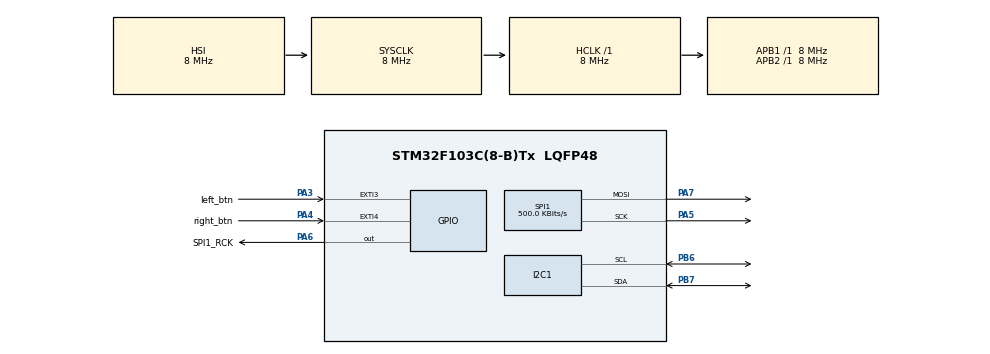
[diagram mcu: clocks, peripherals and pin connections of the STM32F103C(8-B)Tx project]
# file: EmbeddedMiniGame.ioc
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Mcu.Family=STM32F1
Mcu.Name=STM32F103C(8-B)Tx
Mcu.Package=LQFP48
NVIC.EXTI3_IRQn=true\:0\:0\:false\:false\:true\:true\:true\:true
NVIC.EXTI4_IRQn=true\:0\:0\:false\:false\:true\:true\:true\:true
NVIC.PriorityGroup=NVIC_PRIORITYGROUP_4
NVIC.TIM2_IRQn=true\:0\:0\:false\:false\:true\:true\:true\:true
NVIC.TIM3_IRQn=true\:0\:0\:false\:false\:true\:true\:true\:true
PA13.Mode=Serial_Wire
PA13.Signal=SYS_JTMS-SWDIO
PA14.Mode=Serial_Wire
PA14.Signal=SYS_JTCK-SWCLK
PA3.GPIO_Label=left_btn
PA3.GPIO_ModeDefaultEXTI=GPIO_MODE_IT_RISING_FALLING
PA3.GPIO_PuPd=GPIO_PULLUP
PA3.Signal=GPXTI3
PA4.GPIO_Label=right_btn
PA4.GPIO_ModeDefaultEXTI=GPIO_MODE_IT_RISING_FALLING
PA4.GPIO_PuPd=GPIO_PULLUP
PA4.Signal=GPXTI4
PA5.Mode=TX_Only_Simplex_Unidirect_Master
PA5.Signal=SPI1_SCK
PA6.GPIO_Label=SPI1_RCK
PA6.GPIO_PuPd=GPIO_PULLDOWN
PA6.GPIO_Speed=GPIO_SPEED_FREQ_HIGH
PA6.Signal=GPIO_Output
PA7.Mode=TX_Only_Simplex_Unidirect_Master
PA7.Signal=SPI1_MOSI
PB6.Mode=I2C
PB6.Signal=I2C1_SCL
PB7.Mode=I2C
PB7.Signal=I2C1_SDA
ProjectManager.HeapSize=0x200
ProjectManager.StackSize=0x400
ProjectManager.TargetToolchain=STM32CubeIDE
RCC.AHBFreq_Value=8000000
RCC.APB1Freq_Value=8000000
RCC.APB1TimFreq_Value=8000000
RCC.APB2Freq_Value=8000000
RCC.APB2TimFreq_Value=8000000
RCC.HCLKFreq_Value=8000000
RCC.SYSCLKFreq_VALUE=8000000
RCC.USBFreq_Value=8000000
SPI1.BaudRatePrescaler=SPI_BAUDRATEPRESCALER_16
SPI1.CLKPhase=SPI_PHASE_2EDGE
SPI1.CLKPolarity=SPI_POLARITY_HIGH
SPI1.CalculateBaudRate=500.0 KBits/s
SPI1.Direction=SPI_DIRECTION_2LINES
SPI1.Mode=SPI_MODE_MASTER
SPI1.VirtualType=VM_MASTER
TIM2.Period=3000-1
TIM2.Prescaler=8000-1
TIM3.Period=2-1
TIM3.Prescaler=8000-1
VP_TIM2_VS_ClockSourceINT.Mode=Internal
VP_TIM2_VS_ClockSourceITR.Mode=TriggerSource_ITR1
VP_TIM3_VS_ClockSourceINT.Mode=Internal
VP_TIM3_VS_ClockSourceITR.Mode=TriggerSource_ITR2
board=custom

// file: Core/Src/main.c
/* USER CODE BEGIN Header */
/**
  ******************************************************************************
  * @file           : main.c
  * @brief          : Main program body
  ******************************************************************************
  * @attention
  *
  * Copyright (c) 2026 STMicroelectronics.
  * All rights reserved.
  *
  * This software is licensed under terms that can be found in the LICENSE file
  * in the root directory of this software component.
  * If no LICENSE file comes with this software, it is provided AS-IS.
  *
  ******************************************************************************
  */
/* USER CODE END Header */
#include "main.h"

/* USER CODE BEGIN Includes */
#include "global.h"
#include "game.h"
#include "ssd1306.h"
#include "fnd.h"
/* USER CODE END Includes */

I2C_HandleTypeDef hi2c1;

SPI_HandleTypeDef hspi1;

TIM_HandleTypeDef htim2;
TIM_HandleTypeDef htim3;

void SystemClock_Config(void);
static void MX_GPIO_Init(void);
static void MX_I2C1_Init(void);
static void MX_TIM2_Init(void);
static void MX_SPI1_Init(void);
static void MX_TIM3_Init(void);

int main(void)
{

  /* MCU Configuration--------------------------------------------------------*/

  /* Reset of all peripherals, Initializes the Flash interface and the Systick. */
  HAL_Init();

  /* Configure the system clock */
  SystemClock_Config();

  /* Initialize all configured peripherals */
  MX_GPIO_Init();
  MX_I2C1_Init();
  MX_TIM2_Init();
  MX_SPI1_Init();
  MX_TIM3_Init();
  /* USER CODE BEGIN 2 */
  if (ssd1306_Init(&hi2c1) != 0) {
  	   	Error_Handler();
  }
  send_init(&hspi1);
  // ??기화�????
  GameIdle(&hi2c1,&htim2,&htim3);
  /* USER CODE END 2 */

  /* Infinite loop */
  /* USER CODE BEGIN WHILE */
  while (1)
  {
	  if(!game.is_start){
		  GameIdle(&hi2c1,&htim2,&htim3);
	  }
	  isStartBtnDown();
	  GameStart();

    /* USER CODE END WHILE */

  }
}

void SystemClock_Config(void)
{
  RCC_OscInitTypeDef RCC_OscInitStruct = {0};
  RCC_ClkInitTypeDef RCC_ClkInitStruct = {0};

  /** Initializes the RCC Oscillators according to the specified parameters
  * in the RCC_OscInitTypeDef structure.
  */
  RCC_OscInitStruct.OscillatorType = RCC_OSCILLATORTYPE_HSI;
  RCC_OscInitStruct.HSIState = RCC_HSI_ON;
  RCC_OscInitStruct.HSICalibrationValue = RCC_HSICALIBRATION_DEFAULT;
  RCC_OscInitStruct.PLL.PLLState = RCC_PLL_NONE;
  if (HAL_RCC_OscConfig(&RCC_OscInitStruct) != HAL_OK)
  {
    Error_Handler();
  }

  /** Initializes the CPU, AHB and APB buses clocks
  */
  RCC_ClkInitStruct.ClockType = RCC_CLOCKTYPE_HCLK|RCC_CLOCKTYPE_SYSCLK
                              |RCC_CLOCKTYPE_PCLK1|RCC_CLOCKTYPE_PCLK2;
  RCC_ClkInitStruct.SYSCLKSource = RCC_SYSCLKSOURCE_HSI;
  RCC_ClkInitStruct.AHBCLKDivider = RCC_SYSCLK_DIV1;
  RCC_ClkInitStruct.APB1CLKDivider = RCC_HCLK_DIV1;
  RCC_ClkInitStruct.APB2CLKDivider = RCC_HCLK_DIV1;

  if (HAL_RCC_ClockConfig(&RCC_ClkInitStruct, FLASH_LATENCY_0) != HAL_OK)
  {
    Error_Handler();
  }
}

static void MX_I2C1_Init(void)
{

  hi2c1.Instance = I2C1;
  hi2c1.Init.ClockSpeed = 100000;
  hi2c1.Init.DutyCycle = I2C_DUTYCYCLE_2;
  hi2c1.Init.OwnAddress1 = 0;
  hi2c1.Init.AddressingMode = I2C_ADDRESSINGMODE_7BIT;
  hi2c1.Init.DualAddressMode = I2C_DUALADDRESS_DISABLE;
  hi2c1.Init.OwnAddress2 = 0;
  hi2c1.Init.GeneralCallMode = I2C_GENERALCALL_DISABLE;
  hi2c1.Init.NoStretchMode = I2C_NOSTRETCH_DISABLE;
  if (HAL_I2C_Init(&hi2c1) != HAL_OK)
  {
    Error_Handler();
  }

}

static void MX_SPI1_Init(void)
{

  /* SPI1 parameter configuration*/
  hspi1.Instance = SPI1;
  hspi1.Init.Mode = SPI_MODE_MASTER;
  hspi1.Init.Direction = SPI_DIRECTION_2LINES;
  hspi1.Init.DataSize = SPI_DATASIZE_8BIT;
  hspi1.Init.CLKPolarity = SPI_POLARITY_HIGH;
  hspi1.Init.CLKPhase = SPI_PHASE_2EDGE;
  hspi1.Init.NSS = SPI_NSS_SOFT;
  hspi1.Init.BaudRatePrescaler = SPI_BAUDRATEPRESCALER_16;
  hspi1.Init.FirstBit = SPI_FIRSTBIT_MSB;
  hspi1.Init.TIMode = SPI_TIMODE_DISABLE;
  hspi1.Init.CRCCalculation = SPI_CRCCALCULATION_DISABLE;
  hspi1.Init.CRCPolynomial = 10;
  if (HAL_SPI_Init(&hspi1) != HAL_OK)
  {
    Error_Handler();
  }

}

static void MX_TIM2_Init(void)
{

  TIM_ClockConfigTypeDef sClockSourceConfig = {0};
  TIM_SlaveConfigTypeDef sSlaveConfig = {0};
  TIM_MasterConfigTypeDef sMasterConfig = {0};

  htim2.Instance = TIM2;
  htim2.Init.Prescaler = 8000-1;
  htim2.Init.CounterMode = TIM_COUNTERMODE_UP;
  htim2.Init.Period = 3000-1;
  htim2.Init.ClockDivision = TIM_CLOCKDIVISION_DIV1;
  htim2.Init.AutoReloadPreload = TIM_AUTORELOAD_PRELOAD_DISABLE;
  if (HAL_TIM_Base_Init(&htim2) != HAL_OK)
  {
    Error_Handler();
  }
  sClockSourceConfig.ClockSource = TIM_CLOCKSOURCE_INTERNAL;
  if (HAL_TIM_ConfigClockSource(&htim2, &sClockSourceConfig) != HAL_OK)
  {
    Error_Handler();
  }
  sSlaveConfig.SlaveMode = TIM_SLAVEMODE_DISABLE;
  sSlaveConfig.InputTrigger = TIM_TS_ITR1;
  if (HAL_TIM_SlaveConfigSynchro(&htim2, &sSlaveConfig) != HAL_OK)
  {
    Error_Handler();
  }
  sMasterConfig.MasterOutputTrigger = TIM_TRGO_RESET;
  sMasterConfig.MasterSlaveMode = TIM_MASTERSLAVEMODE_DISABLE;
  if (HAL_TIMEx_MasterConfigSynchronization(&htim2, &sMasterConfig) != HAL_OK)
  {
    Error_Handler();
  }

}

static void MX_TIM3_Init(void)
{

  TIM_ClockConfigTypeDef sClockSourceConfig = {0};
  TIM_SlaveConfigTypeDef sSlaveConfig = {0};
  TIM_MasterConfigTypeDef sMasterConfig = {0};

  htim3.Instance = TIM3;
  htim3.Init.Prescaler = 8000-1;
  htim3.Init.CounterMode = TIM_COUNTERMODE_UP;
  htim3.Init.Period = 2-1;
  htim3.Init.ClockDivision = TIM_CLOCKDIVISION_DIV1;
  htim3.Init.AutoReloadPreload = TIM_AUTORELOAD_PRELOAD_DISABLE;
  if (HAL_TIM_Base_Init(&htim3) != HAL_OK)
  {
    Error_Handler();
  }
  sClockSourceConfig.ClockSource = TIM_CLOCKSOURCE_INTERNAL;
  if (HAL_TIM_ConfigClockSource(&htim3, &sClockSourceConfig) != HAL_OK)
  {
    Error_Handler();
  }
  sSlaveConfig.SlaveMode = TIM_SLAVEMODE_DISABLE;
  sSlaveConfig.InputTrigger = TIM_TS_ITR2;
  if (HAL_TIM_SlaveConfigSynchro(&htim3, &sSlaveConfig) != HAL_OK)
  {
    Error_Handler();
  }
  sMasterConfig.MasterOutputTrigger = TIM_TRGO_RESET;
  sMasterConfig.MasterSlaveMode = TIM_MASTERSLAVEMODE_DISABLE;
  if (HAL_TIMEx_MasterConfigSynchronization(&htim3, &sMasterConfig) != HAL_OK)
  {
    Error_Handler();
  }

}

static void MX_GPIO_Init(void)
{
  GPIO_InitTypeDef GPIO_InitStruct = {0};

  /* GPIO Ports Clock Enable */
  __HAL_RCC_GPIOA_CLK_ENABLE();
  __HAL_RCC_GPIOB_CLK_ENABLE();

  /*Configure GPIO pin Output Level */
  HAL_GPIO_WritePin(SPI1_RCK_GPIO_Port, SPI1_RCK_Pin, GPIO_PIN_RESET);

  /*Configure GPIO pins : left_btn_Pin right_btn_Pin */
  GPIO_InitStruct.Pin = left_btn_Pin|right_btn_Pin;
  GPIO_InitStruct.Mode = GPIO_MODE_IT_RISING_FALLING;
  GPIO_InitStruct.Pull = GPIO_PULLUP;
  HAL_GPIO_Init(GPIOA, &GPIO_InitStruct);

  /*Configure GPIO pin : SPI1_RCK_Pin */
  GPIO_InitStruct.Pin = SPI1_RCK_Pin;
  GPIO_InitStruct.Mode = GPIO_MODE_OUTPUT_PP;
  GPIO_InitStruct.Pull = GPIO_PULLDOWN;
  GPIO_InitStruct.Speed = GPIO_SPEED_FREQ_HIGH;
  HAL_GPIO_Init(SPI1_RCK_GPIO_Port, &GPIO_InitStruct);

  /* EXTI interrupt init*/
  HAL_NVIC_SetPriority(EXTI3_IRQn, 0, 0);
  HAL_NVIC_EnableIRQ(EXTI3_IRQn);

  HAL_NVIC_SetPriority(EXTI4_IRQn, 0, 0);
  HAL_NVIC_EnableIRQ(EXTI4_IRQn);

}

void Error_Handler(void)
{
  __disable_irq();
  while (1)
  {
  }
}
